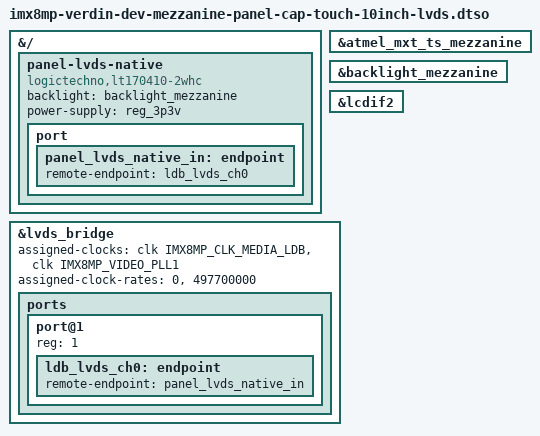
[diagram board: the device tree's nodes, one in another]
// SPDX-License-Identifier: GPL-2.0-or-later OR MIT
/*
 * Copyright (c) Toradex
 *
 * Toradex Capacitive Touch Display 10.1" LVDS on the Verdin iMX8M Plus
 * Mezzanine LVDS interface (J10), used with the Verdin Development Board.
 *
 * https://developer.toradex.com/hardware/accessories/displays/capacitive-touch-display-101inch-lvds
 * https://www.toradex.com/accessories/capacitive-touch-display-10.1-inch-lvds
 * https://developer.toradex.com/hardware/verdin-som-family/add-ons/verdin-imx8m-plus-mezzanine
 * https://www.toradex.com/accessories/verdin-imx8m-plus-mezzanine
 */

/dts-v1/;
/plugin/;

#include <dt-bindings/clock/imx8mp-clock.h>

#include "imx8mp-pinfunc.h"

&{/} {
	panel-lvds-native {
		compatible = "logictechno,lt170410-2whc";
		backlight = <&backlight_mezzanine>;
		power-supply = <&reg_3p3v>;

		port {
			panel_lvds_native_in: endpoint {
				remote-endpoint = <&ldb_lvds_ch0>;
			};
		};
	};
};

&atmel_mxt_ts_mezzanine {
	status = "okay";
};

&backlight_mezzanine {
	status = "okay";
};

&lcdif2 {
	status = "okay";
};

&lvds_bridge {
	assigned-clocks = <&clk IMX8MP_CLK_MEDIA_LDB>,
			  <&clk IMX8MP_VIDEO_PLL1>;
	/*
	 * This display uses 71.1 MHz pixel clock, so IMX8MP_VIDEO_PLL1 needs
	 * to be 7 times 71.1MHz, or 497.7 MHz as the internal divider will
	 * always divide the output LVDS clock by 7.
	 */
	assigned-clock-rates = <0>, <497700000>;

	status = "okay";

	ports {
		#address-cells = <1>;
		#size-cells = <0>;

		port@1 {
			reg = <1>;

			ldb_lvds_ch0: endpoint {
				remote-endpoint = <&panel_lvds_native_in>;
			};
		};
	};
};
